# RasbperryPi register map
File version: 1
Registers are 32-bit, read-write, reset 0x0 unless marked. A register's access mark holds for its fields unless they carry their own. Offsets are from the block's base; [hi:lo] are bit positions; {n}, {i} and the like mark numbered series.

## FPGA_MB — Derived from fpga_microblaze.h
Base 0x7E20B700
0x00 XSYS_BUILD_NUM ro reset not defined
  [31:0] data
0x04 XC0_BUILD_NUM ro reset not defined
  [31:0] data
0x08 XC1_BUILD_NUM ro reset not defined
  [31:0] data
0x0C XPERI_BUILD_NUM ro reset not defined
  [31:0] data
0x10 XH264_BUILD_NUM ro reset not defined
  [31:0] data
0x14 XV3D_BUILD_NUM ro reset not defined
  [31:0] data
{0x14+4i} XSLC{i}_BUILD_NUM ro reset not defined (i=1..3)
  [31:0] data
0x24 CORE_CLK_FREQ ro reset not defined
  [31:0] data
0x28 SDC_CLK_FREQ ro reset not defined
  [31:0] data
0x2C SDC_H264_FREQ ro reset not defined
  [31:0] data
0x30 SDC_V3D_FREQ ro reset not defined
  [31:0] data
0x34 SDC_ISP_FREQ ro reset not defined
  [31:0] data

## GP — Derived from gpio.h apb_id: 0x6770696F
Base 0x7E200000
0x00 FSEL0 30-bit
  [3n+2:3n] FSEL{n:02} (n=0..9)
0x04 FSEL1 30-bit
  [3n-28:3n-30] FSEL{n} (n=10..19)
0x08 FSEL2 30-bit
  [3n-58:3n-60] FSEL{n} (n=20..29)
0x0C FSEL3 30-bit
  [3n-88:3n-90] FSEL{n} (n=30..39)
0x10 FSEL4 30-bit
  [3n-118:3n-120] FSEL{n} (n=40..49)
0x14 FSEL5 30-bit
  [3n-148:3n-150] FSEL{n} (n=50..59)
0x18 FSEL6 30-bit
  [3n-178:3n-180] FSEL{n} (n=60..69)
0x1C SET0
  [31:0] SETn0
0x20 SET1
  [31:0] SETn32
0x24 SET2 6-bit
  [5:0] SETn64
0x28 CLR0
  [31:0] CLRn0
0x2C CLR1
  [31:0] CLRn32
0x30 CLR2 6-bit
  [5:0] CLRn64
0x34 LEV0 ro
  [31:0] LEVn0
0x38 LEV1 ro
  [31:0] LEVn32
0x3C LEV2 6-bit ro
  [5:0] LEVn64
0x40 EDS0
  [31:0] EDSn0
0x44 EDS1
  [31:0] EDSn32
0x48 EDS2 6-bit
  [5:0] EDSn64
0x4C REN0
  [31:0] RENn0
0x50 REN1
  [31:0] RENn32
0x54 REN2 6-bit
  [5:0] RENn64
0x58 FEN0
  [31:0] FENn0
0x5C FEN1
  [31:0] FENn32
0x60 FEN2 6-bit
  [5:0] FENn64
0x64 HEN0
  [31:0] HENn0
0x68 HEN1
  [31:0] HENn32
0x6C HEN2 6-bit
  [5:0] HENn64
0x70 LEN0
  [31:0] LENn0
0x74 LEN1
  [31:0] LENn32
0x78 LEN2 6-bit
  [5:0] LENn64
0x7C AREN0
  [31:0] ARENn0
0x80 AREN1
  [31:0] ARENn32
0x84 AREN2 6-bit
  [5:0] ARENn64
0x88 AFEN0
  [31:0] AFENn0
0x8C AFEN1
  [31:0] AFENn32
0x90 AFEN2 6-bit
  [5:0] AFENn64
0x94 PUD 2-bit

## HDCP — Derived from hdcp.h apb_id: 0x48444350
Base 0x7E809000
0x00 KEY_CTL 3-bit
  [2] DISHDCP, [1] DONE, [0] START
0x04 KEY_ADR 8-bit
  [7:0] data
0x08 KEY_KY0
  [31:0] data
0x0C KEY_KY1 24-bit
  [23:0] data

## HD — Derived from hdmi.h apb_id: 0x48444D49
Base 0x7E808000
0x0C HDM_CTL 10-bit reset 0xF0
  [9] CECRXD, [8] CECOVR, [7:6] RFSTBY, [5:4] PDSTBY, [3] _, [2] SW_RST, [1] ENDIAN, [0] ENABLE
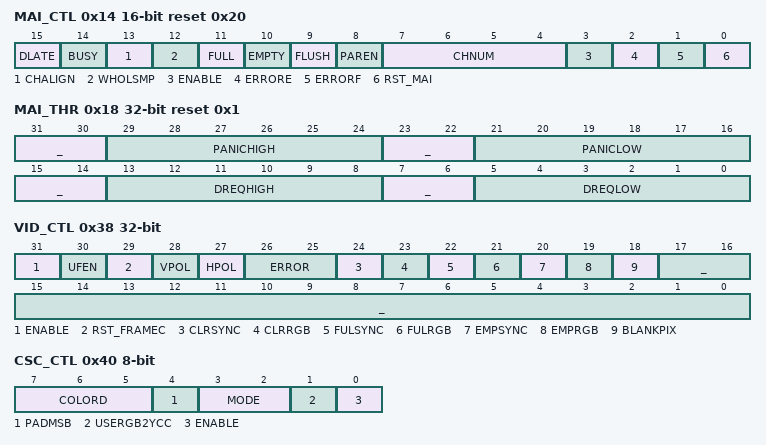
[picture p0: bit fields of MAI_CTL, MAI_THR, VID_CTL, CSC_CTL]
0x14 MAI_CTL 16-bit reset 0x20
  [15] DLATE, [14] BUSY, [13] CHALIGN, [12] WHOLSMP, [11] FULL, [10] EMPTY, [9] FLUSH, [8] PAREN, [7:4] CHNUM, [3] ENABLE, [2] ERRORE, [1] ERRORF, [0] RST_MAI
0x18 MAI_THR reset 0x1
  [31:30] _, [29:24] PANICHIGH, [23:22] _, [21:16] PANICLOW, [15:14] _, [13:8] DREQHIGH, [7:6] _, [5:0] DREQLOW
0x1C MAI_FMT
  [31:0] data
0x20 MAI_DAT
  [31:0] data
0x24 SPARE
  [31:0] data
0x2C MAI_SMP
  [31:0] data
0x38 VID_CTL
  [31] ENABLE, [30] UFEN, [29] RST_FRAMEC, [28] VPOL, [27] HPOL, [26:25] ERROR, [24] CLRSYNC, [23] CLRRGB, [22] FULSYNC, [21] FULRGB, [20] EMPSYNC, [19] EMPRGB, [18] BLANKPIX, [17:0] _
0x40 CSC_CTL 8-bit
  [7:5] COLORD, [4] PADMSB, [3:2] MODE, [1] USERGB2YCC, [0] ENABLE
0x44 CSC_12_11
  [31:0] data
0x48 CSC_14_13
  [31:0] data
0x4C CSC_22_21
  [31:0] data
0x50 CSC_24_23
  [31:0] data
0x54 CSC_32_31
  [31:0] data
0x58 CSC_34_33
  [31:0] data
0x68 FRAME_CNT
  [31:0] data

## SCALER — Derived from hvs.h apb_id: 0x64647276
Base 0x7E400000
0x00 DISPCTRL reset not defined
  [31] HVS_EN, [31:30] VSCL_DIS, [29:28] DSP2_PANIC, [27:26] DSP1_PANIC, [25:24] DSP0_PANIC, [23:20] _, [19:18] DSP3_MUX, [17:16] TILE_WID, [15:13] _, [12:11] DSP2_IRQ_CTRL, [10:9] DSP1_IRQ_CTRL, [8:7] _, [6:0] IRQ_EN
0x04 DISPSTAT reset not defined
  [29:24] DSP2_STATUS, [21:16] DSP1_STATUS, [31:15] DMA_ERR_BIT1, [31:14] DMA_ERR_BIT0, [13:8] DSP0_STATUS, [31:7] DMA_ERR_BIT2, [31:6] RD_IRQ, [31:5] WR_IRQ, [31:4] DMA_IRQ, [31:3] DSP2_IRQ, [31:2] DSP1_IRQ, [31:1] DSP0_IRQ, [31:0] PROF_IRQ
0x08 DISPID reset 0x76
  [31:0] data
0x0C DISPECTRL reset not defined
  [31] SECURE_MODE, [31:30] CR_NE_CTRL, [31:29] CB_NE_CTRL, [31:28] Y_NE_CTRL, [27:26] PROF_TYPE, [31:25] TWOD_SINGLE, [31:24] GT8_BURST, [21:16] POSTED_CTRL, [14:12] POSTED_STATUS, [31:11] CR_BUSY, [31:10] CB_BUSY, [31:9] Y_BUSY, [31:8] BUSY_STATUS, [7] _, [6:0] PANIC_CTRL
0x10 DISPPROF reset not defined
  [31:0] data
0x14 DISPDITHER reset not defined
  [31:0] data
0x18 DISPEOLN reset not defined
  [31:0] data
{0x20+4i} DISPLIST{i} reset not defined (i=0..2)
  [31:0] data
0x2C DISPLSTAT reset not defined
  [31:0] data
{0x30+4i} DISPLACT{i} reset not defined (i=0..2)
  [31:0] data
{0x40+0x10*i} DISPCTRL{i} reset not defined (i=0..2)
  [31:0] data
{0x44+0x10*i} DISPBKGND{i} reset not defined (i=0..2)
  [31:0] data
{0x48+0x10*i} DISPSTAT{i} reset not defined (i=0..2)
  [31:0] data
{0x4C+0x10*i} DISPBASE{i} reset not defined (i=0..2)
  [31:0] data
0x70 DISPALPHA2 reset not defined
  [31:0] data
0x78 DISPGAMADR reset not defined
  [31:0] data
0x80 OLEDOFFS reset not defined
  [31:0] data
{0x84+4i} OLEDCOEF{i} reset not defined (i=0..2)
  [31:0] data
{0xC0+8i} DISPSLAVE{i} reset not defined (i=0..2)
  [31:0] data
0xE0 DISPGAMDAT reset not defined
  [31:0] data
